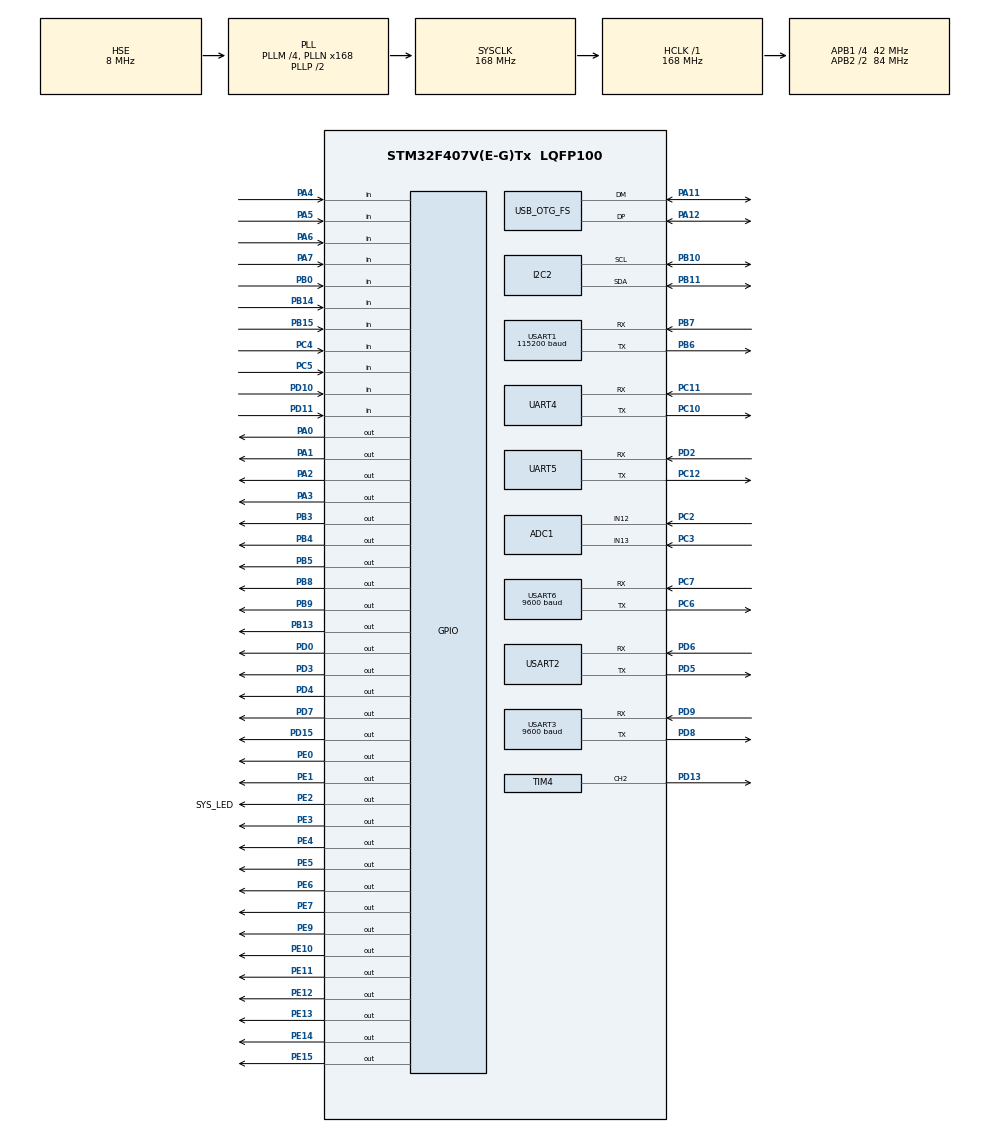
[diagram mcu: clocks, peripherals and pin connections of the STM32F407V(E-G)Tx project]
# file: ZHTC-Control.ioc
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ADC1.Channel-0\#ChannelRegularConversion=ADC_CHANNEL_13
ADC1.NbrOfConversionFlag=1
ADC1.Rank-0\#ChannelRegularConversion=1
ADC1.SamplingTime-0\#ChannelRegularConversion=ADC_SAMPLETIME_3CYCLES
ADC1.master=1
Dma.Request0=USART1_TX
Dma.Request1=USART1_RX
Dma.Request10=USART3_RX
Dma.Request11=USART3_TX
Dma.Request2=USART6_RX
Dma.Request3=USART6_TX
Dma.Request4=UART5_RX
Dma.Request5=UART5_TX
Dma.Request6=UART4_RX
Dma.Request7=UART4_TX
Dma.Request8=USART2_RX
Dma.Request9=USART2_TX
Dma.UART4_RX.6.Direction=DMA_PERIPH_TO_MEMORY
Dma.UART4_RX.6.FIFOMode=DMA_FIFOMODE_DISABLE
Dma.UART4_RX.6.Instance=DMA1_Stream2
Dma.UART4_RX.6.MemDataAlignment=DMA_MDATAALIGN_BYTE
Dma.UART4_RX.6.MemInc=DMA_MINC_ENABLE
Dma.UART4_RX.6.Mode=DMA_NORMAL
Dma.UART4_RX.6.PeriphDataAlignment=DMA_PDATAALIGN_BYTE
Dma.UART4_RX.6.PeriphInc=DMA_PINC_DISABLE
Dma.UART4_RX.6.Priority=DMA_PRIORITY_LOW
Dma.UART4_TX.7.Direction=DMA_MEMORY_TO_PERIPH
Dma.UART4_TX.7.FIFOMode=DMA_FIFOMODE_DISABLE
Dma.UART4_TX.7.Instance=DMA1_Stream4
Dma.UART4_TX.7.MemDataAlignment=DMA_MDATAALIGN_BYTE
Dma.UART4_TX.7.MemInc=DMA_MINC_ENABLE
Dma.UART4_TX.7.Mode=DMA_NORMAL
Dma.UART4_TX.7.PeriphDataAlignment=DMA_PDATAALIGN_BYTE
Dma.UART4_TX.7.PeriphInc=DMA_PINC_DISABLE
Dma.UART4_TX.7.Priority=DMA_PRIORITY_LOW
Dma.UART5_RX.4.Direction=DMA_PERIPH_TO_MEMORY
Dma.UART5_RX.4.FIFOMode=DMA_FIFOMODE_DISABLE
Dma.UART5_RX.4.Instance=DMA1_Stream0
Dma.UART5_RX.4.MemDataAlignment=DMA_MDATAALIGN_BYTE
Dma.UART5_RX.4.MemInc=DMA_MINC_ENABLE
Dma.UART5_RX.4.Mode=DMA_NORMAL
Dma.UART5_RX.4.PeriphDataAlignment=DMA_PDATAALIGN_BYTE
Dma.UART5_RX.4.PeriphInc=DMA_PINC_DISABLE
Dma.UART5_RX.4.Priority=DMA_PRIORITY_LOW
Dma.UART5_TX.5.Direction=DMA_MEMORY_TO_PERIPH
Dma.UART5_TX.5.FIFOMode=DMA_FIFOMODE_DISABLE
Dma.UART5_TX.5.Instance=DMA1_Stream7
Dma.UART5_TX.5.MemDataAlignment=DMA_MDATAALIGN_BYTE
Dma.UART5_TX.5.MemInc=DMA_MINC_ENABLE
Dma.UART5_TX.5.Mode=DMA_NORMAL
Dma.UART5_TX.5.PeriphDataAlignment=DMA_PDATAALIGN_BYTE
Dma.UART5_TX.5.PeriphInc=DMA_PINC_DISABLE
Dma.UART5_TX.5.Priority=DMA_PRIORITY_LOW
Dma.USART1_RX.1.Direction=DMA_PERIPH_TO_MEMORY
Dma.USART1_RX.1.FIFOMode=DMA_FIFOMODE_DISABLE
Dma.USART1_RX.1.Instance=DMA2_Stream2
Dma.USART1_RX.1.MemDataAlignment=DMA_MDATAALIGN_BYTE
Dma.USART1_RX.1.MemInc=DMA_MINC_ENABLE
Dma.USART1_RX.1.Mode=DMA_NORMAL
Dma.USART1_RX.1.PeriphDataAlignment=DMA_PDATAALIGN_BYTE
Dma.USART1_RX.1.PeriphInc=DMA_PINC_DISABLE
Dma.USART1_RX.1.Priority=DMA_PRIORITY_LOW
Dma.USART1_TX.0.Direction=DMA_MEMORY_TO_PERIPH
Dma.USART1_TX.0.FIFOMode=DMA_FIFOMODE_DISABLE
Dma.USART1_TX.0.Instance=DMA2_Stream7
Dma.USART1_TX.0.MemDataAlignment=DMA_MDATAALIGN_BYTE
Dma.USART1_TX.0.MemInc=DMA_MINC_ENABLE
Dma.USART1_TX.0.Mode=DMA_NORMAL
Dma.USART1_TX.0.PeriphDataAlignment=DMA_PDATAALIGN_BYTE
Dma.USART1_TX.0.PeriphInc=DMA_PINC_DISABLE
Dma.USART1_TX.0.Priority=DMA_PRIORITY_LOW
Dma.USART2_RX.8.Direction=DMA_PERIPH_TO_MEMORY
Dma.USART2_RX.8.FIFOMode=DMA_FIFOMODE_DISABLE
Dma.USART2_RX.8.Instance=DMA1_Stream5
Dma.USART2_RX.8.MemDataAlignment=DMA_MDATAALIGN_BYTE
Dma.USART2_RX.8.MemInc=DMA_MINC_ENABLE
Dma.USART2_RX.8.Mode=DMA_NORMAL
Dma.USART2_RX.8.PeriphDataAlignment=DMA_PDATAALIGN_BYTE
Dma.USART2_RX.8.PeriphInc=DMA_PINC_DISABLE
Dma.USART2_RX.8.Priority=DMA_PRIORITY_LOW
Dma.USART2_TX.9.Direction=DMA_MEMORY_TO_PERIPH
Dma.USART2_TX.9.FIFOMode=DMA_FIFOMODE_DISABLE
Dma.USART2_TX.9.Instance=DMA1_Stream6
Dma.USART2_TX.9.MemDataAlignment=DMA_MDATAALIGN_BYTE
Dma.USART2_TX.9.MemInc=DMA_MINC_ENABLE
Dma.USART2_TX.9.Mode=DMA_NORMAL
Dma.USART2_TX.9.PeriphDataAlignment=DMA_PDATAALIGN_BYTE
Dma.USART2_TX.9.PeriphInc=DMA_PINC_DISABLE
Dma.USART2_TX.9.Priority=DMA_PRIORITY_LOW
Dma.USART3_RX.10.Direction=DMA_PERIPH_TO_MEMORY
Dma.USART3_RX.10.FIFOMode=DMA_FIFOMODE_DISABLE
Dma.USART3_RX.10.Instance=DMA1_Stream1
Dma.USART3_RX.10.MemDataAlignment=DMA_MDATAALIGN_BYTE
Dma.USART3_RX.10.MemInc=DMA_MINC_ENABLE
Dma.USART3_RX.10.Mode=DMA_NORMAL
Dma.USART3_RX.10.PeriphDataAlignment=DMA_PDATAALIGN_BYTE
Dma.USART3_RX.10.PeriphInc=DMA_PINC_DISABLE
Dma.USART3_RX.10.Priority=DMA_PRIORITY_LOW
Dma.USART3_TX.11.Direction=DMA_MEMORY_TO_PERIPH
Dma.USART3_TX.11.FIFOMode=DMA_FIFOMODE_DISABLE
Dma.USART3_TX.11.Instance=DMA1_Stream3
Dma.USART3_TX.11.MemDataAlignment=DMA_MDATAALIGN_BYTE
Dma.USART3_TX.11.MemInc=DMA_MINC_ENABLE
Dma.USART3_TX.11.Mode=DMA_NORMAL
Dma.USART3_TX.11.PeriphDataAlignment=DMA_PDATAALIGN_BYTE
Dma.USART3_TX.11.PeriphInc=DMA_PINC_DISABLE
Dma.USART3_TX.11.Priority=DMA_PRIORITY_LOW
Dma.USART6_RX.2.Direction=DMA_PERIPH_TO_MEMORY
Dma.USART6_RX.2.FIFOMode=DMA_FIFOMODE_DISABLE
Dma.USART6_RX.2.Instance=DMA2_Stream1
Dma.USART6_RX.2.MemDataAlignment=DMA_MDATAALIGN_BYTE
Dma.USART6_RX.2.MemInc=DMA_MINC_ENABLE
Dma.USART6_RX.2.Mode=DMA_NORMAL
Dma.USART6_RX.2.PeriphDataAlignment=DMA_PDATAALIGN_BYTE
Dma.USART6_RX.2.PeriphInc=DMA_PINC_DISABLE
Dma.USART6_RX.2.Priority=DMA_PRIORITY_LOW
Dma.USART6_TX.3.Direction=DMA_MEMORY_TO_PERIPH
Dma.USART6_TX.3.FIFOMode=DMA_FIFOMODE_DISABLE
Dma.USART6_TX.3.Instance=DMA2_Stream6
Dma.USART6_TX.3.MemDataAlignment=DMA_MDATAALIGN_BYTE
Dma.USART6_TX.3.MemInc=DMA_MINC_ENABLE
Dma.USART6_TX.3.Mode=DMA_NORMAL
Dma.USART6_TX.3.PeriphDataAlignment=DMA_PDATAALIGN_BYTE
Dma.USART6_TX.3.PeriphInc=DMA_PINC_DISABLE
Dma.USART6_TX.3.Priority=DMA_PRIORITY_LOW
FREERTOS.Tasks01=defaultTask,24,256,StartDefaultTask,Default,NULL,Dynamic,NULL,NULL
FREERTOS.configENABLE_FPU=1
FREERTOS.configTOTAL_HEAP_SIZE=61440
Mcu.Family=STM32F4
Mcu.Name=STM32F407V(E-G)Tx
Mcu.Package=LQFP100
NVIC.DMA1_Stream0_IRQn=true\:9\:0\:true\:false\:true\:true\:false\:true\:true
NVIC.DMA1_Stream1_IRQn=true\:9\:0\:true\:false\:true\:true\:false\:true\:true
NVIC.DMA1_Stream2_IRQn=true\:9\:0\:true\:false\:true\:true\:false\:true\:true
NVIC.DMA1_Stream3_IRQn=true\:9\:0\:true\:false\:true\:true\:false\:true\:true
NVIC.DMA1_Stream4_IRQn=true\:9\:0\:true\:false\:true\:true\:false\:true\:true
NVIC.DMA1_Stream5_IRQn=true\:9\:0\:true\:false\:true\:true\:false\:true\:true
NVIC.DMA1_Stream6_IRQn=true\:9\:0\:true\:false\:true\:true\:false\:true\:true
NVIC.DMA1_Stream7_IRQn=true\:9\:0\:true\:false\:true\:true\:false\:true\:true
NVIC.DMA2_Stream1_IRQn=true\:9\:0\:true\:false\:true\:true\:false\:true\:true
NVIC.DMA2_Stream2_IRQn=true\:7\:0\:true\:false\:true\:true\:false\:true\:true
NVIC.DMA2_Stream6_IRQn=true\:9\:0\:true\:false\:true\:true\:false\:true\:true
NVIC.DMA2_Stream7_IRQn=true\:7\:0\:true\:false\:true\:true\:false\:true\:true
NVIC.OTG_FS_IRQn=true\:5\:0\:true\:false\:true\:true\:true\:true\:true
NVIC.PriorityGroup=NVIC_PRIORITYGROUP_4
NVIC.TIM1_UP_TIM10_IRQn=true\:5\:0\:false\:false\:true\:true\:true\:true\:true
NVIC.TIM6_DAC_IRQn=true\:15\:0\:true\:false\:true\:true\:true\:true\:true
NVIC.UART4_IRQn=true\:8\:0\:true\:false\:true\:true\:true\:true\:true
NVIC.UART5_IRQn=true\:8\:0\:true\:false\:true\:true\:true\:true\:true
NVIC.USART1_IRQn=true\:6\:0\:true\:false\:true\:true\:true\:true\:true
NVIC.USART2_IRQn=true\:8\:0\:true\:false\:true\:true\:true\:true\:true
NVIC.USART3_IRQn=true\:8\:0\:true\:false\:true\:true\:true\:true\:true
NVIC.USART6_IRQn=true\:8\:0\:true\:false\:true\:true\:true\:true\:true
PA0-WKUP.GPIO_ModeDefaultOutputPP=GPIO_MODE_OUTPUT_PP
PA0-WKUP.GPIO_PuPd=GPIO_PULLUP
PA0-WKUP.GPIO_Speed=GPIO_SPEED_FREQ_MEDIUM
PA0-WKUP.PinState=GPIO_PIN_RESET
PA0-WKUP.Signal=GPIO_Output
PA1.GPIO_ModeDefaultOutputPP=GPIO_MODE_OUTPUT_PP
PA1.GPIO_PuPd=GPIO_PULLUP
PA1.GPIO_Speed=GPIO_SPEED_FREQ_MEDIUM
PA1.PinState=GPIO_PIN_RESET
PA1.Signal=GPIO_Output
PA11.Mode=Device_Only
PA11.Signal=USB_OTG_FS_DM
PA12.Mode=Device_Only
PA12.Signal=USB_OTG_FS_DP
PA13.Mode=Serial_Wire
PA13.Signal=SYS_JTMS-SWDIO
PA14.Mode=Serial_Wire
PA14.Signal=SYS_JTCK-SWCLK
PA2.GPIO_ModeDefaultOutputPP=GPIO_MODE_OUTPUT_PP
PA2.GPIO_PuPd=GPIO_PULLUP
PA2.GPIO_Speed=GPIO_SPEED_FREQ_MEDIUM
PA2.PinState=GPIO_PIN_SET
PA2.Signal=GPIO_Output
PA3.GPIO_ModeDefaultOutputPP=GPIO_MODE_OUTPUT_PP
PA3.GPIO_PuPd=GPIO_PULLUP
PA3.GPIO_Speed=GPIO_SPEED_FREQ_LOW
PA3.PinState=GPIO_PIN_RESET
PA3.Signal=GPIO_Output
PA4.GPIO_PuPd=GPIO_PULLUP
PA4.Signal=GPIO_Input
PA5.GPIO_PuPd=GPIO_PULLUP
PA5.Signal=GPIO_Input
PA6.GPIO_PuPd=GPIO_PULLUP
PA6.Signal=GPIO_Input
PA7.GPIO_PuPd=GPIO_PULLDOWN
PA7.Signal=GPIO_Input
PB0.GPIO_PuPd=GPIO_PULLUP
PB0.Signal=GPIO_Input
PB10.Mode=I2C
PB10.Signal=I2C2_SCL
PB11.Mode=I2C
PB11.Signal=I2C2_SDA
PB13.GPIO_PuPd=GPIO_PULLUP
PB13.GPIO_Speed=GPIO_SPEED_FREQ_VERY_HIGH
PB13.PinState=GPIO_PIN_SET
PB13.Signal=GPIO_Output
PB14.GPIO_PuPd=GPIO_PULLUP
PB14.Signal=GPIO_Input
PB15.GPIO_PuPd=GPIO_PULLUP
PB15.Signal=GPIO_Input
PB3.GPIO_ModeDefaultOutputPP=GPIO_MODE_OUTPUT_PP
PB3.GPIO_PuPd=GPIO_PULLUP
PB3.GPIO_Speed=GPIO_SPEED_FREQ_MEDIUM
PB3.Signal=GPIO_Output
PB4.GPIO_ModeDefaultOutputPP=GPIO_MODE_OUTPUT_PP
PB4.GPIO_PuPd=GPIO_PULLUP
PB4.GPIO_Speed=GPIO_SPEED_FREQ_MEDIUM
PB4.Signal=GPIO_Output
PB5.GPIO_ModeDefaultOutputPP=GPIO_MODE_OUTPUT_PP
PB5.GPIO_PuPd=GPIO_PULLUP
PB5.GPIO_Speed=GPIO_SPEED_FREQ_MEDIUM
PB5.PinState=GPIO_PIN_RESET
PB5.Signal=GPIO_Output
PB6.Mode=Asynchronous
PB6.Signal=USART1_TX
PB7.GPIO_PuPd=GPIO_NOPULL
PB7.Mode=Asynchronous
PB7.Signal=USART1_RX
PB8.GPIO_ModeDefaultOutputPP=GPIO_MODE_OUTPUT_PP
PB8.GPIO_PuPd=GPIO_PULLUP
PB8.GPIO_Speed=GPIO_SPEED_FREQ_MEDIUM
PB8.Signal=GPIO_Output
PB9.GPIO_PuPd=GPIO_PULLUP
PB9.GPIO_Speed=GPIO_SPEED_FREQ_MEDIUM
PB9.Signal=GPIO_Output
PC10.Mode=Asynchronous
PC10.Signal=UART4_TX
PC11.Mode=Asynchronous
PC11.Signal=UART4_RX
PC12.Mode=Asynchronous
PC12.Signal=UART5_TX
PC2.Signal=ADCx_IN12
PC3.Signal=ADCx_IN13
PC4.GPIO_PuPd=GPIO_PULLDOWN
PC4.Signal=GPIO_Input
PC5.GPIO_PuPd=GPIO_PULLUP
PC5.Signal=GPIO_Input
PC6.Mode=Asynchronous
PC6.Signal=USART6_TX
PC7.Mode=Asynchronous
PC7.Signal=USART6_RX
PD0.GPIO_ModeDefaultOutputPP=GPIO_MODE_OUTPUT_PP
PD0.GPIO_PuPd=GPIO_PULLDOWN
PD0.GPIO_Speed=GPIO_SPEED_FREQ_MEDIUM
PD0.Signal=GPIO_Output
PD10.GPIO_PuPd=GPIO_PULLUP
PD10.Signal=GPIO_Input
PD11.GPIO_PuPd=GPIO_PULLUP
PD11.Signal=GPIO_Input
PD13.Signal=S_TIM4_CH2
PD15.GPIO_PuPd=GPIO_PULLDOWN
PD15.GPIO_Speed=GPIO_SPEED_FREQ_MEDIUM
PD15.Signal=GPIO_Output
PD2.Mode=Asynchronous
PD2.Signal=UART5_RX
PD3.GPIO_ModeDefaultOutputPP=GPIO_MODE_OUTPUT_PP
PD3.GPIO_PuPd=GPIO_PULLDOWN
PD3.GPIO_Speed=GPIO_SPEED_FREQ_MEDIUM
PD3.Signal=GPIO_Output
PD4.GPIO_PuPd=GPIO_PULLUP
PD4.GPIO_Speed=GPIO_SPEED_FREQ_MEDIUM
PD4.Signal=GPIO_Output
PD5.Mode=Asynchronous
PD5.Signal=USART2_TX
PD6.Mode=Asynchronous
PD6.Signal=USART2_RX
PD7.GPIO_PuPd=GPIO_PULLUP
PD7.GPIO_Speed=GPIO_SPEED_FREQ_MEDIUM
PD7.Signal=GPIO_Output
PD8.Mode=Asynchronous
PD8.Signal=USART3_TX
PD9.Mode=Asynchronous
PD9.Signal=USART3_RX
PE0.GPIO_PuPd=GPIO_PULLUP
PE0.GPIO_Speed=GPIO_SPEED_FREQ_MEDIUM
PE0.Signal=GPIO_Output
PE1.GPIO_PuPd=GPIO_PULLUP
PE1.GPIO_Speed=GPIO_SPEED_FREQ_MEDIUM
PE1.Signal=GPIO_Output
PE10.GPIO_PuPd=GPIO_PULLDOWN
PE10.GPIO_Speed=GPIO_SPEED_FREQ_MEDIUM
PE10.Signal=GPIO_Output
PE11.GPIO_PuPd=GPIO_PULLUP
PE11.GPIO_Speed=GPIO_SPEED_FREQ_MEDIUM
PE11.Signal=GPIO_Output
PE12.GPIO_PuPd=GPIO_PULLDOWN
PE12.GPIO_Speed=GPIO_SPEED_FREQ_MEDIUM
PE12.Signal=GPIO_Output
PE13.GPIO_PuPd=GPIO_PULLUP
PE13.GPIO_Speed=GPIO_SPEED_FREQ_MEDIUM
PE13.Signal=GPIO_Output
PE14.GPIO_ModeDefaultOutputPP=GPIO_MODE_OUTPUT_PP
PE14.GPIO_PuPd=GPIO_PULLUP
PE14.GPIO_Speed=GPIO_SPEED_FREQ_MEDIUM
PE14.Signal=GPIO_Output
PE15.GPIO_PuPd=GPIO_PULLUP
PE15.GPIO_Speed=GPIO_SPEED_FREQ_MEDIUM
PE15.Signal=GPIO_Output
PE2.GPIO_Label=SYS_LED
PE2.GPIO_ModeDefaultOutputPP=GPIO_MODE_OUTPUT_OD
PE2.GPIO_PuPd=GPIO_NOPULL
PE2.GPIO_Speed=GPIO_SPEED_FREQ_MEDIUM
PE2.PinState=GPIO_PIN_SET
PE2.Signal=GPIO_Output
PE3.GPIO_PuPd=GPIO_PULLUP
PE3.GPIO_Speed=GPIO_SPEED_FREQ_MEDIUM
PE3.Signal=GPIO_Output
PE4.GPIO_PuPd=GPIO_PULLUP
PE4.GPIO_Speed=GPIO_SPEED_FREQ_MEDIUM
PE4.Signal=GPIO_Output
PE5.GPIO_PuPd=GPIO_PULLUP
PE5.GPIO_Speed=GPIO_SPEED_FREQ_MEDIUM
PE5.Signal=GPIO_Output
PE6.GPIO_PuPd=GPIO_PULLUP
PE6.GPIO_Speed=GPIO_SPEED_FREQ_MEDIUM
PE6.Signal=GPIO_Output
PE7.GPIO_PuPd=GPIO_PULLDOWN
PE7.GPIO_Speed=GPIO_SPEED_FREQ_MEDIUM
PE7.Signal=GPIO_Output
PE9.GPIO_PuPd=GPIO_PULLUP
PE9.GPIO_Speed=GPIO_SPEED_FREQ_MEDIUM
PE9.Signal=GPIO_Output
PH0-OSC_IN.Mode=HSE-External-Oscillator
PH0-OSC_IN.Signal=RCC_OSC_IN
PH1-OSC_OUT.Mode=HSE-External-Oscillator
PH1-OSC_OUT.Signal=RCC_OSC_OUT
ProjectManager.HeapSize=0x1000
ProjectManager.StackSize=0x800
ProjectManager.TargetToolchain=MDK-ARM V5.27
RCC.48MHZClocksFreq_Value=48000000
RCC.AHBFreq_Value=168000000
RCC.APB1CLKDivider=RCC_HCLK_DIV4
RCC.APB1Freq_Value=42000000
RCC.APB1TimFreq_Value=84000000
RCC.APB2CLKDivider=RCC_HCLK_DIV2
RCC.APB2Freq_Value=84000000
RCC.APB2TimFreq_Value=168000000
RCC.CortexFreq_Value=168000000
RCC.HCLKFreq_Value=168000000
RCC.HSE_VALUE=8000000
RCC.HSI_VALUE=16000000
RCC.LSE_VALUE=32768
RCC.PLLM=4
RCC.PLLN=168
RCC.PLLQ=7
RCC.SYSCLKFreq_VALUE=168000000
RCC.SYSCLKSource=RCC_SYSCLKSOURCE_PLLCLK
RCC.VCOOutputFreq_Value=336000000
SH.ADCx_IN12.0=ADC1_IN12,IN12
SH.ADCx_IN13.0=ADC1_IN13,IN13
SH.S_TIM4_CH2.0=TIM4_CH2,PWM Generation2 CH2
TIM1.AutoReloadPreload=TIM_AUTORELOAD_PRELOAD_ENABLE
TIM1.Period=8400-1
TIM4.AutoReloadPreload=TIM_AUTORELOAD_PRELOAD_ENABLE
TIM4.Channel-PWM\ Generation2\ CH2=TIM_CHANNEL_2
TIM4.ClockDivision=TIM_CLOCKDIVISION_DIV1
TIM4.OCMode_PWM-PWM\ Generation2\ CH2=TIM_OCMODE_PWM1
TIM4.OCPolarity_2=TIM_OCPOLARITY_LOW
TIM4.Period=4199
TIM6.AutoReloadPreload=TIM_AUTORELOAD_PRELOAD_ENABLE
TIM6.Period=29999
TIM6.Prescaler=83
TIM6.TIM_MasterOutputTrigger=TIM_TRGO_RESET
UART4.VirtualMode=Asynchronous
UART5.VirtualMode=Asynchronous
USART1.BaudRate=115200
USART1.VirtualMode=VM_ASYNC
USART2.VirtualMode=VM_ASYNC
USART3.BaudRate=9600
USART3.VirtualMode=VM_ASYNC
USART6.BaudRate=9600
USART6.VirtualMode=VM_ASYNC
USB_DEVICE.CLASS_NAME_FS=CDC
USB_DEVICE.VirtualMode-CDC_FS=Cdc
USB_DEVICE.VirtualModeFS=Cdc_FS
USB_OTG_FS.VirtualMode=Device_Only
VP_FREERTOS_VS_CMSIS_V2.Mode=CMSIS_V2
VP_TIM1_VS_ClockSourceINT.Mode=Internal
VP_TIM4_VS_ClockSourceINT.Mode=Internal
VP_TIM6_VS_ClockSourceINT.Mode=Enable_Timer
VP_USB_DEVICE_VS_USB_DEVICE_CDC_FS.Mode=CDC_FS
board=custom

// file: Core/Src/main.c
/* USER CODE BEGIN Header */
/**
  ******************************************************************************
  * @file           : main.c
  * @brief          : Main program body
  ******************************************************************************
  * @attention
  *
  * Copyright (c) 2024 STMicroelectronics.
  * All rights reserved.
  *
  * This software is licensed under terms that can be found in the LICENSE file
  * in the root directory of this software component.
  * If no LICENSE file comes with this software, it is provided AS-IS.
  *
  ******************************************************************************
  */
/* USER CODE END Header */
#include "main.h"
#include "cmsis_os.h"
#include "usb_device.h"

/* USER CODE BEGIN Includes */
#include "app.h"
/* USER CODE END Includes */

ADC_HandleTypeDef hadc1;

I2C_HandleTypeDef hi2c2;

TIM_HandleTypeDef htim1;
TIM_HandleTypeDef htim4;
TIM_HandleTypeDef htim6;

UART_HandleTypeDef huart4;
UART_HandleTypeDef huart5;
UART_HandleTypeDef huart1;
UART_HandleTypeDef huart2;
UART_HandleTypeDef huart3;
UART_HandleTypeDef huart6;
DMA_HandleTypeDef hdma_uart4_rx;
DMA_HandleTypeDef hdma_uart4_tx;
DMA_HandleTypeDef hdma_uart5_rx;
DMA_HandleTypeDef hdma_uart5_tx;
DMA_HandleTypeDef hdma_usart1_tx;
DMA_HandleTypeDef hdma_usart1_rx;
DMA_HandleTypeDef hdma_usart2_rx;
DMA_HandleTypeDef hdma_usart2_tx;
DMA_HandleTypeDef hdma_usart3_rx;
DMA_HandleTypeDef hdma_usart3_tx;
DMA_HandleTypeDef hdma_usart6_rx;
DMA_HandleTypeDef hdma_usart6_tx;

/* Definitions for defaultTask */
osThreadId_t defaultTaskHandle;
const osThreadAttr_t defaultTask_attributes = {
  .name = "defaultTask",
  .stack_size = 256 * 4,
  .priority = (osPriority_t) osPriorityNormal,
};

void SystemClock_Config(void);
static void MX_GPIO_Init(void);
static void MX_DMA_Init(void);
static void MX_TIM1_Init(void);
static void MX_USART1_UART_Init(void);
static void MX_USART2_UART_Init(void);
static void MX_USART3_UART_Init(void);
static void MX_UART5_Init(void);
static void MX_USART6_UART_Init(void);
static void MX_ADC1_Init(void);
static void MX_UART4_Init(void);
static void MX_TIM4_Init(void);
static void MX_TIM6_Init(void);
static void MX_I2C2_Init(void);
void StartDefaultTask(void *argument);

int main(void)
{

  /* MCU Configuration--------------------------------------------------------*/

  /* Reset of all peripherals, Initializes the Flash interface and the Systick. */
  HAL_Init();

  /* Configure the system clock */
  SystemClock_Config();

  /* Initialize all configured peripherals */
  MX_GPIO_Init();
  MX_DMA_Init();
  MX_TIM1_Init();
  MX_USART1_UART_Init();
  MX_USART2_UART_Init();
  MX_USART3_UART_Init();
  MX_UART5_Init();
  MX_USART6_UART_Init();
  MX_ADC1_Init();
  MX_UART4_Init();
  MX_TIM4_Init();
  MX_TIM6_Init();
  MX_I2C2_Init();

  /* Init scheduler */
  osKernelInitialize();

  /* Create the thread(s) */
  /* creation of defaultTask */
  defaultTaskHandle = osThreadNew(StartDefaultTask, NULL, &defaultTask_attributes);

  /* Start scheduler */
  osKernelStart();

  /* We should never get here as control is now taken by the scheduler */
  /* Infinite loop */
  while (1)
  {

  }
}

void SystemClock_Config(void)
{
  RCC_OscInitTypeDef RCC_OscInitStruct = {0};
  RCC_ClkInitTypeDef RCC_ClkInitStruct = {0};

  /** Configure the main internal regulator output voltage
  */
  __HAL_RCC_PWR_CLK_ENABLE();
  __HAL_PWR_VOLTAGESCALING_CONFIG(PWR_REGULATOR_VOLTAGE_SCALE1);

  /** Initializes the RCC Oscillators according to the specified parameters
  * in the RCC_OscInitTypeDef structure.
  */
  RCC_OscInitStruct.OscillatorType = RCC_OSCILLATORTYPE_HSE;
  RCC_OscInitStruct.HSEState = RCC_HSE_ON;
  RCC_OscInitStruct.PLL.PLLState = RCC_PLL_ON;
  RCC_OscInitStruct.PLL.PLLSource = RCC_PLLSOURCE_HSE;
  RCC_OscInitStruct.PLL.PLLM = 4;
  RCC_OscInitStruct.PLL.PLLN = 168;
  RCC_OscInitStruct.PLL.PLLP = RCC_PLLP_DIV2;
  RCC_OscInitStruct.PLL.PLLQ = 7;
  if (HAL_RCC_OscConfig(&RCC_OscInitStruct) != HAL_OK)
  {
    Error_Handler();
  }

  /** Initializes the CPU, AHB and APB buses clocks
  */
  RCC_ClkInitStruct.ClockType = RCC_CLOCKTYPE_HCLK|RCC_CLOCKTYPE_SYSCLK
                              |RCC_CLOCKTYPE_PCLK1|RCC_CLOCKTYPE_PCLK2;
  RCC_ClkInitStruct.SYSCLKSource = RCC_SYSCLKSOURCE_PLLCLK;
  RCC_ClkInitStruct.AHBCLKDivider = RCC_SYSCLK_DIV1;
  RCC_ClkInitStruct.APB1CLKDivider = RCC_HCLK_DIV4;
  RCC_ClkInitStruct.APB2CLKDivider = RCC_HCLK_DIV2;

  if (HAL_RCC_ClockConfig(&RCC_ClkInitStruct, FLASH_LATENCY_5) != HAL_OK)
  {
    Error_Handler();
  }
}

static void MX_ADC1_Init(void)
{

  ADC_ChannelConfTypeDef sConfig = {0};

  /** Configure the global features of the ADC (Clock, Resolution, Data Alignment and number of conversion)
  */
  hadc1.Instance = ADC1;
  hadc1.Init.ClockPrescaler = ADC_CLOCK_SYNC_PCLK_DIV4;
  hadc1.Init.Resolution = ADC_RESOLUTION_12B;
  hadc1.Init.ScanConvMode = DISABLE;
  hadc1.Init.ContinuousConvMode = DISABLE;
  hadc1.Init.DiscontinuousConvMode = DISABLE;
  hadc1.Init.ExternalTrigConvEdge = ADC_EXTERNALTRIGCONVEDGE_NONE;
  hadc1.Init.ExternalTrigConv = ADC_SOFTWARE_START;
  hadc1.Init.DataAlign = ADC_DATAALIGN_RIGHT;
  hadc1.Init.NbrOfConversion = 1;
  hadc1.Init.DMAContinuousRequests = DISABLE;
  hadc1.Init.EOCSelection = ADC_EOC_SINGLE_CONV;
  if (HAL_ADC_Init(&hadc1) != HAL_OK)
  {
    Error_Handler();
  }

  /** Configure for the selected ADC regular channel its corresponding rank in the sequencer and its sample time.
  */
  sConfig.Channel = ADC_CHANNEL_13;
  sConfig.Rank = 1;
  sConfig.SamplingTime = ADC_SAMPLETIME_3CYCLES;
  if (HAL_ADC_ConfigChannel(&hadc1, &sConfig) != HAL_OK)
  {
    Error_Handler();
  }

}

static void MX_I2C2_Init(void)
{

  hi2c2.Instance = I2C2;
  hi2c2.Init.ClockSpeed = 100000;
  hi2c2.Init.DutyCycle = I2C_DUTYCYCLE_2;
  hi2c2.Init.OwnAddress1 = 0;
  hi2c2.Init.AddressingMode = I2C_ADDRESSINGMODE_7BIT;
  hi2c2.Init.DualAddressMode = I2C_DUALADDRESS_DISABLE;
  hi2c2.Init.OwnAddress2 = 0;
  hi2c2.Init.GeneralCallMode = I2C_GENERALCALL_DISABLE;
  hi2c2.Init.NoStretchMode = I2C_NOSTRETCH_DISABLE;
  if (HAL_I2C_Init(&hi2c2) != HAL_OK)
  {
    Error_Handler();
  }

}

static void MX_TIM1_Init(void)
{

  TIM_ClockConfigTypeDef sClockSourceConfig = {0};
  TIM_MasterConfigTypeDef sMasterConfig = {0};

  htim1.Instance = TIM1;
  htim1.Init.Prescaler = 0;
  htim1.Init.CounterMode = TIM_COUNTERMODE_UP;
  htim1.Init.Period = 8400-1;
  htim1.Init.ClockDivision = TIM_CLOCKDIVISION_DIV1;
  htim1.Init.RepetitionCounter = 0;
  htim1.Init.AutoReloadPreload = TIM_AUTORELOAD_PRELOAD_ENABLE;
  if (HAL_TIM_Base_Init(&htim1) != HAL_OK)
  {
    Error_Handler();
  }
  sClockSourceConfig.ClockSource = TIM_CLOCKSOURCE_INTERNAL;
  if (HAL_TIM_ConfigClockSource(&htim1, &sClockSourceConfig) != HAL_OK)
  {
    Error_Handler();
  }
  sMasterConfig.MasterOutputTrigger = TIM_TRGO_RESET;
  sMasterConfig.MasterSlaveMode = TIM_MASTERSLAVEMODE_DISABLE;
  if (HAL_TIMEx_MasterConfigSynchronization(&htim1, &sMasterConfig) != HAL_OK)
  {
    Error_Handler();
  }

}

static void MX_TIM4_Init(void)
{

  TIM_ClockConfigTypeDef sClockSourceConfig = {0};
  TIM_MasterConfigTypeDef sMasterConfig = {0};
  TIM_OC_InitTypeDef sConfigOC = {0};

  htim4.Instance = TIM4;
  htim4.Init.Prescaler = 0;
  htim4.Init.CounterMode = TIM_COUNTERMODE_UP;
  htim4.Init.Period = 4199;
  htim4.Init.ClockDivision = TIM_CLOCKDIVISION_DIV1;
  htim4.Init.AutoReloadPreload = TIM_AUTORELOAD_PRELOAD_ENABLE;
  if (HAL_TIM_Base_Init(&htim4) != HAL_OK)
  {
    Error_Handler();
  }
  sClockSourceConfig.ClockSource = TIM_CLOCKSOURCE_INTERNAL;
  if (HAL_TIM_ConfigClockSource(&htim4, &sClockSourceConfig) != HAL_OK)
  {
    Error_Handler();
  }
  if (HAL_TIM_PWM_Init(&htim4) != HAL_OK)
  {
    Error_Handler();
  }
  sMasterConfig.MasterOutputTrigger = TIM_TRGO_RESET;
  sMasterConfig.MasterSlaveMode = TIM_MASTERSLAVEMODE_DISABLE;
  if (HAL_TIMEx_MasterConfigSynchronization(&htim4, &sMasterConfig) != HAL_OK)
  {
    Error_Handler();
  }
  sConfigOC.OCMode = TIM_OCMODE_PWM1;
  sConfigOC.Pulse = 0;
  sConfigOC.OCPolarity = TIM_OCPOLARITY_LOW;
  sConfigOC.OCFastMode = TIM_OCFAST_DISABLE;
  if (HAL_TIM_PWM_ConfigChannel(&htim4, &sConfigOC, TIM_CHANNEL_2) != HAL_OK)
  {
    Error_Handler();
  }
  HAL_TIM_MspPostInit(&htim4);

}

static void MX_TIM6_Init(void)
{

  TIM_MasterConfigTypeDef sMasterConfig = {0};

  htim6.Instance = TIM6;
  htim6.Init.Prescaler = 83;
  htim6.Init.CounterMode = TIM_COUNTERMODE_UP;
  htim6.Init.Period = 29999;
  htim6.Init.AutoReloadPreload = TIM_AUTORELOAD_PRELOAD_ENABLE;
  if (HAL_TIM_Base_Init(&htim6) != HAL_OK)
  {
    Error_Handler();
  }
  sMasterConfig.MasterOutputTrigger = TIM_TRGO_RESET;
  sMasterConfig.MasterSlaveMode = TIM_MASTERSLAVEMODE_DISABLE;
  if (HAL_TIMEx_MasterConfigSynchronization(&htim6, &sMasterConfig) != HAL_OK)
  {
    Error_Handler();
  }

}

static void MX_UART4_Init(void)
{

  huart4.Instance = UART4;
  huart4.Init.BaudRate = 115200;
  huart4.Init.WordLength = UART_WORDLENGTH_8B;
  huart4.Init.StopBits = UART_STOPBITS_1;
  huart4.Init.Parity = UART_PARITY_NONE;
  huart4.Init.Mode = UART_MODE_TX_RX;
  huart4.Init.HwFlowCtl = UART_HWCONTROL_NONE;
  huart4.Init.OverSampling = UART_OVERSAMPLING_16;
  if (HAL_UART_Init(&huart4) != HAL_OK)
  {
    Error_Handler();
  }

}

static void MX_UART5_Init(void)
{

  huart5.Instance = UART5;
  huart5.Init.BaudRate = 115200;
  huart5.Init.WordLength = UART_WORDLENGTH_8B;
  huart5.Init.StopBits = UART_STOPBITS_1;
  huart5.Init.Parity = UART_PARITY_NONE;
  huart5.Init.Mode = UART_MODE_TX_RX;
  huart5.Init.HwFlowCtl = UART_HWCONTROL_NONE;
  huart5.Init.OverSampling = UART_OVERSAMPLING_16;
  if (HAL_UART_Init(&huart5) != HAL_OK)
  {
    Error_Handler();
  }

}

static void MX_USART1_UART_Init(void)
{

  huart1.Instance = USART1;
  huart1.Init.BaudRate = 115200;
  huart1.Init.WordLength = UART_WORDLENGTH_8B;
  huart1.Init.StopBits = UART_STOPBITS_1;
  huart1.Init.Parity = UART_PARITY_NONE;
  huart1.Init.Mode = UART_MODE_TX_RX;
  huart1.Init.HwFlowCtl = UART_HWCONTROL_NONE;
  huart1.Init.OverSampling = UART_OVERSAMPLING_16;
  if (HAL_UART_Init(&huart1) != HAL_OK)
  {
    Error_Handler();
  }

}

static void MX_USART2_UART_Init(void)
{

  huart2.Instance = USART2;
  huart2.Init.BaudRate = 115200;
  huart2.Init.WordLength = UART_WORDLENGTH_8B;
  huart2.Init.StopBits = UART_STOPBITS_1;
  huart2.Init.Parity = UART_PARITY_NONE;
  huart2.Init.Mode = UART_MODE_TX_RX;
  huart2.Init.HwFlowCtl = UART_HWCONTROL_NONE;
  huart2.Init.OverSampling = UART_OVERSAMPLING_16;
  if (HAL_UART_Init(&huart2) != HAL_OK)
  {
    Error_Handler();
  }

}

static void MX_USART3_UART_Init(void)
{

  huart3.Instance = USART3;
  huart3.Init.BaudRate = 9600;
  huart3.Init.WordLength = UART_WORDLENGTH_8B;
  huart3.Init.StopBits = UART_STOPBITS_1;
  huart3.Init.Parity = UART_PARITY_NONE;
  huart3.Init.Mode = UART_MODE_TX_RX;
  huart3.Init.HwFlowCtl = UART_HWCONTROL_NONE;
  huart3.Init.OverSampling = UART_OVERSAMPLING_16;
  if (HAL_UART_Init(&huart3) != HAL_OK)
  {
    Error_Handler();
  }

}

static void MX_USART6_UART_Init(void)
{

  huart6.Instance = USART6;
  huart6.Init.BaudRate = 9600;
  huart6.Init.WordLength = UART_WORDLENGTH_8B;
  huart6.Init.StopBits = UART_STOPBITS_1;
  huart6.Init.Parity = UART_PARITY_NONE;
  huart6.Init.Mode = UART_MODE_TX_RX;
  huart6.Init.HwFlowCtl = UART_HWCONTROL_NONE;
  huart6.Init.OverSampling = UART_OVERSAMPLING_16;
  if (HAL_UART_Init(&huart6) != HAL_OK)
  {
    Error_Handler();
  }

}

static void MX_DMA_Init(void)
{

  /* DMA controller clock enable */
  __HAL_RCC_DMA2_CLK_ENABLE();
  __HAL_RCC_DMA1_CLK_ENABLE();

  /* DMA interrupt init */
  /* DMA1_Stream0_IRQn interrupt configuration */
  HAL_NVIC_SetPriority(DMA1_Stream0_IRQn, 9, 0);
  HAL_NVIC_EnableIRQ(DMA1_Stream0_IRQn);
  /* DMA1_Stream1_IRQn interrupt configuration */
  HAL_NVIC_SetPriority(DMA1_Stream1_IRQn, 9, 0);
  HAL_NVIC_EnableIRQ(DMA1_Stream1_IRQn);
  /* DMA1_Stream2_IRQn interrupt configuration */
  HAL_NVIC_SetPriority(DMA1_Stream2_IRQn, 9, 0);
  HAL_NVIC_EnableIRQ(DMA1_Stream2_IRQn);
  /* DMA1_Stream3_IRQn interrupt configuration */
  HAL_NVIC_SetPriority(DMA1_Stream3_IRQn, 9, 0);
  HAL_NVIC_EnableIRQ(DMA1_Stream3_IRQn);
  /* DMA1_Stream4_IRQn interrupt configuration */
  HAL_NVIC_SetPriority(DMA1_Stream4_IRQn, 9, 0);
  HAL_NVIC_EnableIRQ(DMA1_Stream4_IRQn);
  /* DMA1_Stream5_IRQn interrupt configuration */
  HAL_NVIC_SetPriority(DMA1_Stream5_IRQn, 9, 0);
  HAL_NVIC_EnableIRQ(DMA1_Stream5_IRQn);
  /* DMA1_Stream6_IRQn interrupt configuration */
  HAL_NVIC_SetPriority(DMA1_Stream6_IRQn, 9, 0);
  HAL_NVIC_EnableIRQ(DMA1_Stream6_IRQn);
  /* DMA1_Stream7_IRQn interrupt configuration */
  HAL_NVIC_SetPriority(DMA1_Stream7_IRQn, 9, 0);
  HAL_NVIC_EnableIRQ(DMA1_Stream7_IRQn);
  /* DMA2_Stream1_IRQn interrupt configuration */
  HAL_NVIC_SetPriority(DMA2_Stream1_IRQn, 9, 0);
  HAL_NVIC_EnableIRQ(DMA2_Stream1_IRQn);
  /* DMA2_Stream2_IRQn interrupt configuration */
  HAL_NVIC_SetPriority(DMA2_Stream2_IRQn, 7, 0);
  HAL_NVIC_EnableIRQ(DMA2_Stream2_IRQn);
  /* DMA2_Stream6_IRQn interrupt configuration */
  HAL_NVIC_SetPriority(DMA2_Stream6_IRQn, 9, 0);
  HAL_NVIC_EnableIRQ(DMA2_Stream6_IRQn);
  /* DMA2_Stream7_IRQn interrupt configuration */
  HAL_NVIC_SetPriority(DMA2_Stream7_IRQn, 7, 0);
  HAL_NVIC_EnableIRQ(DMA2_Stream7_IRQn);

}

static void MX_GPIO_Init(void)
{
  GPIO_InitTypeDef GPIO_InitStruct = {0};

  /* GPIO Ports Clock Enable */
  __HAL_RCC_GPIOE_CLK_ENABLE();
  __HAL_RCC_GPIOH_CLK_ENABLE();
  __HAL_RCC_GPIOC_CLK_ENABLE();
  __HAL_RCC_GPIOA_CLK_ENABLE();
  __HAL_RCC_GPIOB_CLK_ENABLE();
  __HAL_RCC_GPIOD_CLK_ENABLE();

  /*Configure GPIO pin Output Level */
  HAL_GPIO_WritePin(SYS_LED_GPIO_Port, SYS_LED_Pin, GPIO_PIN_SET);

  /*Configure GPIO pin Output Level */
  HAL_GPIO_WritePin(GPIOE, GPIO_PIN_3|GPIO_PIN_4|GPIO_PIN_5|GPIO_PIN_6
                          |GPIO_PIN_7|GPIO_PIN_9|GPIO_PIN_10|GPIO_PIN_11
                          |GPIO_PIN_12|GPIO_PIN_13|GPIO_PIN_14|GPIO_PIN_15
                          |GPIO_PIN_0|GPIO_PIN_1, GPIO_PIN_RESET);

  /*Configure GPIO pin Output Level */
  HAL_GPIO_WritePin(GPIOA, GPIO_PIN_0|GPIO_PIN_1|GPIO_PIN_3, GPIO_PIN_RESET);

  /*Configure GPIO pin Output Level */
  HAL_GPIO_WritePin(GPIOA, GPIO_PIN_2, GPIO_PIN_SET);

  /*Configure GPIO pin Output Level */
  HAL_GPIO_WritePin(GPIOB, GPIO_PIN_13, GPIO_PIN_SET);

  /*Configure GPIO pin Output Level */
  HAL_GPIO_WritePin(GPIOD, GPIO_PIN_15|GPIO_PIN_0|GPIO_PIN_3|GPIO_PIN_4
                          |GPIO_PIN_7, GPIO_PIN_RESET);

  /*Configure GPIO pin Output Level */
  HAL_GPIO_WritePin(GPIOB, GPIO_PIN_3|GPIO_PIN_4|GPIO_PIN_5|GPIO_PIN_8
                          |GPIO_PIN_9, GPIO_PIN_RESET);

  /*Configure GPIO pin : SYS_LED_Pin */
  GPIO_InitStruct.Pin = SYS_LED_Pin;
  GPIO_InitStruct.Mode = GPIO_MODE_OUTPUT_OD;
  GPIO_InitStruct.Pull = GPIO_NOPULL;
  GPIO_InitStruct.Speed = GPIO_SPEED_FREQ_MEDIUM;
  HAL_GPIO_Init(SYS_LED_GPIO_Port, &GPIO_InitStruct);

  /*Configure GPIO pins : PE3 PE4 PE5 PE6
                           PE9 PE11 PE13 PE14
                           PE15 PE0 PE1 */
  GPIO_InitStruct.Pin = GPIO_PIN_3|GPIO_PIN_4|GPIO_PIN_5|GPIO_PIN_6
                          |GPIO_PIN_9|GPIO_PIN_11|GPIO_PIN_13|GPIO_PIN_14
                          |GPIO_PIN_15|GPIO_PIN_0|GPIO_PIN_1;
  GPIO_InitStruct.Mode = GPIO_MODE_OUTPUT_PP;
  GPIO_InitStruct.Pull = GPIO_PULLUP;
  GPIO_InitStruct.Speed = GPIO_SPEED_FREQ_MEDIUM;
  HAL_GPIO_Init(GPIOE, &GPIO_InitStruct);

  /*Configure GPIO pins : PA0 PA1 PA2 */
  GPIO_InitStruct.Pin = GPIO_PIN_0|GPIO_PIN_1|GPIO_PIN_2;
  GPIO_InitStruct.Mode = GPIO_MODE_OUTPUT_PP;
  GPIO_InitStruct.Pull = GPIO_PULLUP;
  GPIO_InitStruct.Speed = GPIO_SPEED_FREQ_MEDIUM;
  HAL_GPIO_Init(GPIOA, &GPIO_InitStruct);

  /*Configure GPIO pin : PA3 */
  GPIO_InitStruct.Pin = GPIO_PIN_3;
  GPIO_InitStruct.Mode = GPIO_MODE_OUTPUT_PP;
  GPIO_InitStruct.Pull = GPIO_PULLUP;
  GPIO_InitStruct.Speed = GPIO_SPEED_FREQ_LOW;
  HAL_GPIO_Init(GPIOA, &GPIO_InitStruct);

  /*Configure GPIO pins : PA4 PA5 PA6 */
  GPIO_InitStruct.Pin = GPIO_PIN_4|GPIO_PIN_5|GPIO_PIN_6;
  GPIO_InitStruct.Mode = GPIO_MODE_INPUT;
  GPIO_InitStruct.Pull = GPIO_PULLUP;
  HAL_GPIO_Init(GPIOA, &GPIO_InitStruct);

  /*Configure GPIO pin : PA7 */
  GPIO_InitStruct.Pin = GPIO_PIN_7;
  GPIO_InitStruct.Mode = GPIO_MODE_INPUT;
  GPIO_InitStruct.Pull = GPIO_PULLDOWN;
  HAL_GPIO_Init(GPIOA, &GPIO_InitStruct);

  /*Configure GPIO pin : PC4 */
  GPIO_InitStruct.Pin = GPIO_PIN_4;
  GPIO_InitStruct.Mode = GPIO_MODE_INPUT;
  GPIO_InitStruct.Pull = GPIO_PULLDOWN;
  HAL_GPIO_Init(GPIOC, &GPIO_InitStruct);

  /*Configure GPIO pin : PC5 */
  GPIO_InitStruct.Pin = GPIO_PIN_5;
  GPIO_InitStruct.Mode = GPIO_MODE_INPUT;
  GPIO_InitStruct.Pull = GPIO_PULLUP;
  HAL_GPIO_Init(GPIOC, &GPIO_InitStruct);

  /*Configure GPIO pins : PB0 PB14 PB15 */
  GPIO_InitStruct.Pin = GPIO_PIN_0|GPIO_PIN_14|GPIO_PIN_15;
  GPIO_InitStruct.Mode = GPIO_MODE_INPUT;
  GPIO_InitStruct.Pull = GPIO_PULLUP;
  HAL_GPIO_Init(GPIOB, &GPIO_InitStruct);

  /*Configure GPIO pins : PE7 PE10 PE12 */
  GPIO_InitStruct.Pin = GPIO_PIN_7|GPIO_PIN_10|GPIO_PIN_12;
  GPIO_InitStruct.Mode = GPIO_MODE_OUTPUT_PP;
  GPIO_InitStruct.Pull = GPIO_PULLDOWN;
  GPIO_InitStruct.Speed = GPIO_SPEED_FREQ_MEDIUM;
  HAL_GPIO_Init(GPIOE, &GPIO_InitStruct);

  /*Configure GPIO pin : PB13 */
  GPIO_InitStruct.Pin = GPIO_PIN_13;
  GPIO_InitStruct.Mode = GPIO_MODE_OUTPUT_PP;
  GPIO_InitStruct.Pull = GPIO_PULLUP;
  GPIO_InitStruct.Speed = GPIO_SPEED_FREQ_VERY_HIGH;
  HAL_GPIO_Init(GPIOB, &GPIO_InitStruct);

  /*Configure GPIO pins : PD10 PD11 */
  GPIO_InitStruct.Pin = GPIO_PIN_10|GPIO_PIN_11;
  GPIO_InitStruct.Mode = GPIO_MODE_INPUT;
  GPIO_InitStruct.Pull = GPIO_PULLUP;
  HAL_GPIO_Init(GPIOD, &GPIO_InitStruct);

  /*Configure GPIO pins : PD15 PD0 PD3 */
  GPIO_InitStruct.Pin = GPIO_PIN_15|GPIO_PIN_0|GPIO_PIN_3;
  GPIO_InitStruct.Mode = GPIO_MODE_OUTPUT_PP;
  GPIO_InitStruct.Pull = GPIO_PULLDOWN;
  GPIO_InitStruct.Speed = GPIO_SPEED_FREQ_MEDIUM;
  HAL_GPIO_Init(GPIOD, &GPIO_InitStruct);

  /*Configure GPIO pins : PD4 PD7 */
  GPIO_InitStruct.Pin = GPIO_PIN_4|GPIO_PIN_7;
  GPIO_InitStruct.Mode = GPIO_MODE_OUTPUT_PP;
  GPIO_InitStruct.Pull = GPIO_PULLUP;
  GPIO_InitStruct.Speed = GPIO_SPEED_FREQ_MEDIUM;
  HAL_GPIO_Init(GPIOD, &GPIO_InitStruct);

  /*Configure GPIO pins : PB3 PB4 PB5 PB8
                           PB9 */
  GPIO_InitStruct.Pin = GPIO_PIN_3|GPIO_PIN_4|GPIO_PIN_5|GPIO_PIN_8
                          |GPIO_PIN_9;
  GPIO_InitStruct.Mode = GPIO_MODE_OUTPUT_PP;
  GPIO_InitStruct.Pull = GPIO_PULLUP;
  GPIO_InitStruct.Speed = GPIO_SPEED_FREQ_MEDIUM;
  HAL_GPIO_Init(GPIOB, &GPIO_InitStruct);

}

void StartDefaultTask(void *argument)
{
  /* init code for USB_DEVICE */
  MX_USB_DEVICE_Init();
  /* USER CODE BEGIN 5 */
  app_init();
  /* Infinite loop */
  for(;;)
  {
	// HAL_GPIO_TogglePin(SYS_LED_GPIO_Port, SYS_LED_Pin);
	app_run();
	sys_run_led_toggle();
    osDelay(1000);
  }
  /* USER CODE END 5 */
}

void Error_Handler(void)
{
  __disable_irq();
  while (1)
  {
  }
}
